# iostm8af61a8 register map
Registers are 8-bit, access not given, no defined reset value unless marked. A register's access mark holds for its fields unless they carry their own. Addresses are absolute; registers are grouped by the start of their names; [hi:lo] are bit positions; {n}, {i} and the like mark numbered series.

## LINUART
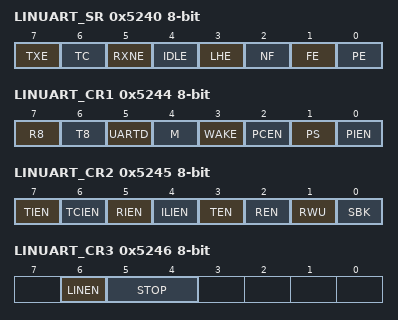
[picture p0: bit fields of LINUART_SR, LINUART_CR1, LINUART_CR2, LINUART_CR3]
0x5240 LINUART_SR — LINUART status register
  [7] TXE ro, [6] TC, [5] RXNE, [4] IDLE ro, [3] LHE ro, [2] NF ro, [1] FE ro, [0] PE ro
0x5241 LINUART_DR — LINUART data register
0x5242 LINUART_BRR1 — LINUART baud rate register 1
  [7:0] LDIV
0x5243 LINUART_BRR2 — LINUART baud rate register 2
  [7:0] LDIV
0x5244 LINUART_CR1 — LINUART control register 1
  [7] R8, [6] T8, [5] UARTD, [4] M, [3] WAKE, [2] PCEN, [1] PS, [0] PIEN
0x5245 LINUART_CR2 — LINUART control register 2
  [7] TIEN, [6] TCIEN, [5] RIEN, [4] ILIEN, [3] TEN, [2] REN, [1] RWU, [0] SBK
0x5246 LINUART_CR3 — LINUART control register 3
  [6] LINEN, [5:4] STOP
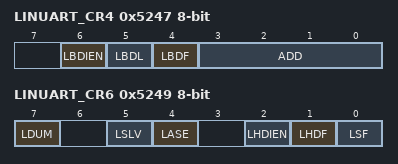
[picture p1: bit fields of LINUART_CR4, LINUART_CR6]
0x5247 LINUART_CR4 — LINUART control register 4
  [6] LBDIEN, [5] LBDL, [4] LBDF, [3:0] ADD
0x5249 LINUART_CR6 — LINUART control register 6
  [7] LDUM, [5] LSLV, [4] LASE, [2] LHDIEN, [1] LHDF, [0] LSF

## TIM1
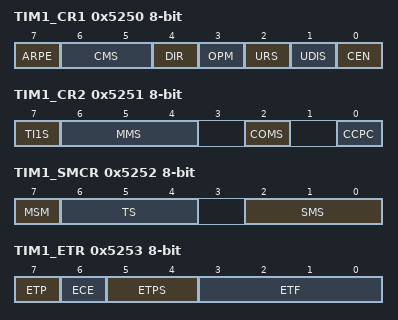
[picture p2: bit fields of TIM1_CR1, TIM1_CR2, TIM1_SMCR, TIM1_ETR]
0x5250 TIM1_CR1 — TIM1 control register 1
  [7] ARPE, [6:5] CMS, [4] DIR, [3] OPM, [2] URS, [1] UDIS, [0] CEN
0x5251 TIM1_CR2 — TIM1 control register 2
  [7] TI1S, [6:4] MMS, [2] COMS, [0] CCPC
0x5252 TIM1_SMCR — TIM1 slave mode control register
  [7] MSM, [6:4] TS, [2:0] SMS
0x5253 TIM1_ETR — TIM1 external trigger register
  [7] ETP, [6] ECE, [5:4] ETPS, [3:0] ETF
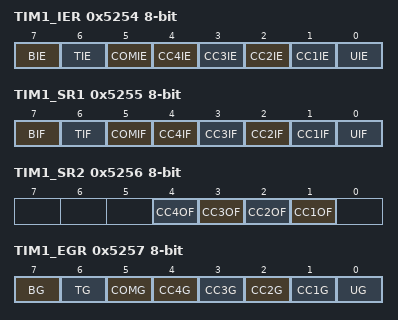
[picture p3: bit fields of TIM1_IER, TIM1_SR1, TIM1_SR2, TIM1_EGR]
0x5254 TIM1_IER — TIM1 interrupt enable register
  [7] BIE, [6] TIE, [5] COMIE, [n] CC{n}IE (n=1..4), [0] UIE
0x5255 TIM1_SR1 — TIM1 status register 1
  [7] BIF, [6] TIF, [5] COMIF, [n] CC{n}IF (n=1..4), [0] UIF
0x5256 TIM1_SR2 — TIM1 status register 2
  [n] CC{n}OF (n=1..4)
0x5257 TIM1_EGR wo — TIM1 event generation register
  [7] BG, [6] TG, [5] COMG, [n] CC{n}G (n=1..4), [0] UG
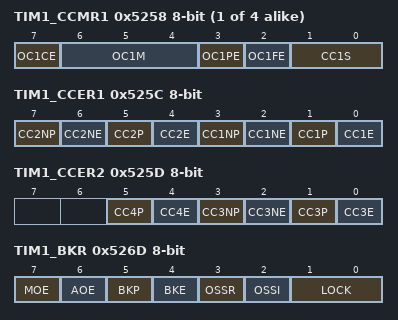
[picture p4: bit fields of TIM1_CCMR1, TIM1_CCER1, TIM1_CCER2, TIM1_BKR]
{0x5257+i} TIM1_CCMR{i} (i=1..4) — TIM1 capture/compare mode register {i}
  [7] OC{i}CE, [6:4] OC{i}M, [3] OC{i}PE, [2] OC{i}FE, [1:0] CC{i}S
0x525C TIM1_CCER1 — TIM1 capture/compare enable register 1
  [7] CC2NP, [6] CC2NE, [5] CC2P, [4] CC2E, [3] CC1NP, [2] CC1NE, [1] CC1P, [0] CC1E
0x525D TIM1_CCER2 — TIM1 capture/compare enable register 2
  [5] CC4P, [4] CC4E, [3] CC3NP, [2] CC3NE, [1] CC3P, [0] CC3E
0x525E TIM1_CNTRH — TIM1 counter high
  [7:0] CNT
0x525F TIM1_CNTRL — TIM1 counter Low
  [7:0] CNT
0x5260 TIM1_PSCRH — TIM1 prescaler register high
  [7:0] PSC
0x5261 TIM1_PSCRL — TIM1 prescaler register low
  [7:0] PSC
0x5262 TIM1_ARRH — TIM1 auto-reload register high
  [7:0] ARR
0x5263 TIM1_ARRL — TIM1 auto-reload register low
  [7:0] ARR
0x5264 TIM1_RCR — TIM1 repetition counter register
  [7:0] REP
0x5265 TIM1_CCR1H — TIM1 capture/compare register 1 high
  [7:0] CCR
0x5266 TIM1_CCR1L — TIM1 capture/compare register 1 low
  [7:0] CCR
{0x5263+2i} TIM1_CCR{i}H (i=2..4) — TIM1 capture/compare register {i} high
  [7:0] CCR{i}
{0x5264+2i} TIM1_CCR{i}L (i=2..4) — TIM1 capture/compare register {i} low
  [7:0] CCR{i}
0x526D TIM1_BKR — TIM1 break register
  [7] MOE, [6] AOE, [5] BKP, [4] BKE, [3] OSSR, [2] OSSI, [1:0] LOCK
0x526E TIM1_DTR — TIM1 deadtime register
  [7:0] DTG
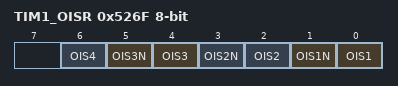
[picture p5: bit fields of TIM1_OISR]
0x526F TIM1_OISR — TIM1 output idle state register
  [2n-2] OIS{n} (n=1..4), [5] OIS3N, [3] OIS2N, [1] OIS1N

## TIM2
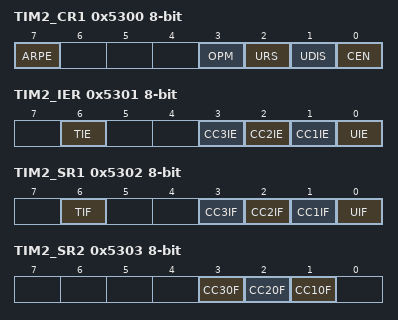
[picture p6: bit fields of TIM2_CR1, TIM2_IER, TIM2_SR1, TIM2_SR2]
0x5300 TIM2_CR1 — TIM2 control register 1
  [7] ARPE, [3] OPM, [2] URS, [1] UDIS, [0] CEN
0x5301 TIM2_IER — TIM2 interrupt enable register
  [6] TIE, [3] CC3IE, [2] CC2IE, [1] CC1IE, [0] UIE
0x5302 TIM2_SR1 — TIM2 status register 1
  [6] TIF, [3] CC3IF, [2] CC2IF, [1] CC1IF, [0] UIF
0x5303 TIM2_SR2 — TIM2 status register 2
  [3] CC30F, [2] CC20F, [1] CC10F
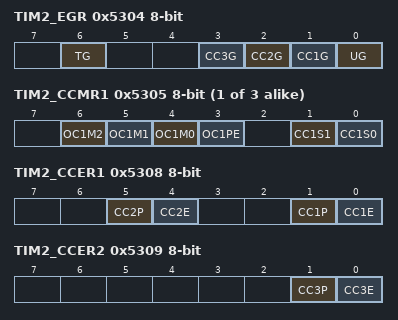
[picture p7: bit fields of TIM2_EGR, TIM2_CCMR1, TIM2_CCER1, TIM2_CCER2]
0x5304 TIM2_EGR — TIM2 event generation register
  [6] TG, [3] CC3G, [2] CC2G, [1] CC1G, [0] UG
{0x5304+i} TIM2_CCMR{i} (i=1..3) — TIM2 capture/compare mode register {i}
  [6] OC{i}M2, [5] OC{i}M1, [4] OC{i}M0, [3] OC{i}PE, [1] CC{i}S1, [0] CC{i}S0
0x5308 TIM2_CCER1 — TIM2 capture/compare enable register 1
  [5] CC2P, [4] CC2E, [1] CC1P, [0] CC1E
0x5309 TIM2_CCER2 — TIM2 capture/compare enable register 2
  [1] CC3P, [0] CC3E
0x530A TIM2_CNTRH — TIM2 counter high
  [7:0] CNT
0x530B TIM2_CNTRL — TIM2 counter low
  [7:0] CNT
0x530C TIM2_PSCR — TIM2 prescaler register
  [3:0] PSC
0x530D TIM2_ARRH — TIM2 auto-reload register high
  [7:0] ARR
0x530E TIM2_ARRL — TIM2 auto-reload register low
  [7:0] ARR
0x530F TIM2_CCR1H — TIM2 capture/compare register 1 high
  [7:0] CCR
0x5310 TIM2_CCR1L — TIM2 capture/compare register 1 low
  [7:0] CCR
0x5311 TIM2_CCR2H — TIM2 capture/compare register 2 high
  [7:0] CCR2
0x5312 TIM2_CCR2L — TIM2 capture/compare register 2 low
  [7:0] CCR2
0x5313 TIM2_CCR3H — TIM2 capture/compare register 3 high
  [7:0] CCR3
0x5314 TIM2_CCR3L — TIM2 capture/compare register 3 low
  [7:0] CCR3
